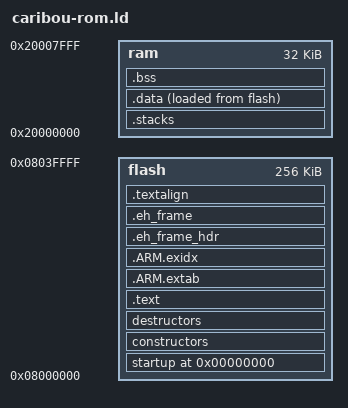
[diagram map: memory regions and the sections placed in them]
/***************************************************************************
 *   Copyright © 2005-2009 by Pike Aerospace Research Corporation          *
 *   mike@pikeaero.com                                                     *
 *                                                                         *
 *   This program is free software; you can redistribute it and/or modify  *
 *   it under the terms of the GNU General Public License as published by  *
 *   the Free Software Foundation; either version 2 of the License, or     *
 *   (at your option) any later version.                                   *
 *                                                                         *
 *   This program is distributed in the hope that it will be useful,       *
 *   but WITHOUT ANY WARRANTY; without even the implied warranty of        *
 *   MERCHANTABILITY or FITNESS FOR A PARTICULAR PURPOSE.  See the         *
 *   GNU General Public License for more details.                          *
 *                                                                         *
 *   You should have received a copy of the GNU General Public License     *
 *   along with this program; if not, write to the                         *
 *   Free Software Foundation, Inc.,                                       *
 *   59 Temple Place - Suite 330, Boston, MA  02111-1307, USA.             *
 ***************************************************************************/
__main_stack_size__     = 0x0200;
__process_stack_size__  = 0x0200;

MEMORY
{
    flash : org = 0x08000000, len = 256k
    ram : org = 0x20000000, len = 32k
}

__ram_start__           = ORIGIN(ram);
__ram_size__            = LENGTH(ram);
__ram_end__             = __ram_start__ + __ram_size__;

SECTIONS
{
    . = 0;
    _text = .;

    startup : ALIGN(16) SUBALIGN(16)
    {
        KEEP(*(.vectors))
    } > flash

    constructors : ALIGN(4) SUBALIGN(4)
    {
        PROVIDE(__init_array_start = .);
        KEEP(*(SORT(.init_array.*)))
        KEEP(*(.init_array))
        PROVIDE(__init_array_end = .);
    } > flash

    destructors : ALIGN(4) SUBALIGN(4)
    {
        PROVIDE(__fini_array_start = .);
        KEEP(*(.fini_array))
        KEEP(*(SORT(.fini_array.*)))
        PROVIDE(__fini_array_end = .);
    } > flash

    .text : ALIGN(16) SUBALIGN(16)
    {
        *(.text.startup.*)
        *(.init)
        *(.text)
        *(.text.*)
        *(.rodata)
        *(.rodata.*)
        *(.glue_7t)
        *(.glue_7)
        *(.gcc*)
    } > flash

    .ARM.extab :
    {
        *(.ARM.extab* .gnu.linkonce.armextab.*)
    } > flash

    .ARM.exidx : {
        PROVIDE(__exidx_start = .);
        *(.ARM.exidx* .gnu.linkonce.armexidx.*)
        PROVIDE(__exidx_end = .);
     } > flash

    .eh_frame_hdr :
    {
        *(.eh_frame_hdr)
    } > flash

    .eh_frame : ONLY_IF_RO
    {
        *(.eh_frame)
    } > flash

    .textalign : ONLY_IF_RO
    {
        . = ALIGN(8);
    } > flash

    _etext = .;
    _textdata = _etext;

    .stacks :
    {
        . = ALIGN(8);
        __main_stack_base__ = .;
        . += __main_stack_size__;
        . = ALIGN(8);
        __main_stack_end__ = .;
        __process_stack_base__ = .;
        __main_thread_stack_base__ = .;
        . += __process_stack_size__;
        . = ALIGN(8);
        __process_stack_end__ = .;
        __main_thread_stack_end__ = .;
    } > ram

    .data :
    {
        . = ALIGN(4);
        PROVIDE(_data = .);
        *(.data)
        . = ALIGN(4);
        *(.data.*)
        . = ALIGN(4);
        *(.ramtext)
        . = ALIGN(4);
        PROVIDE(_edata = .);
    } > ram AT > flash

    .bss :
    {
        . = ALIGN(4);
        PROVIDE(__bss_start__ = .);
        *(.bss)
        . = ALIGN(4);
        *(.bss.*)
        . = ALIGN(4);
        *(COMMON)
        . = ALIGN(4);
        PROVIDE(__bss_end__ = .);
    } > ram
}

PROVIDE(end = .);
_end            = .;

__heap_base__   = _end;
__heap_end__    = __ram_end__;
